VERSION ""

NS_ :

BS_:

BU_: MINI_CELKA ACHTER_BOARD FORE_BOARD ODESC RPI

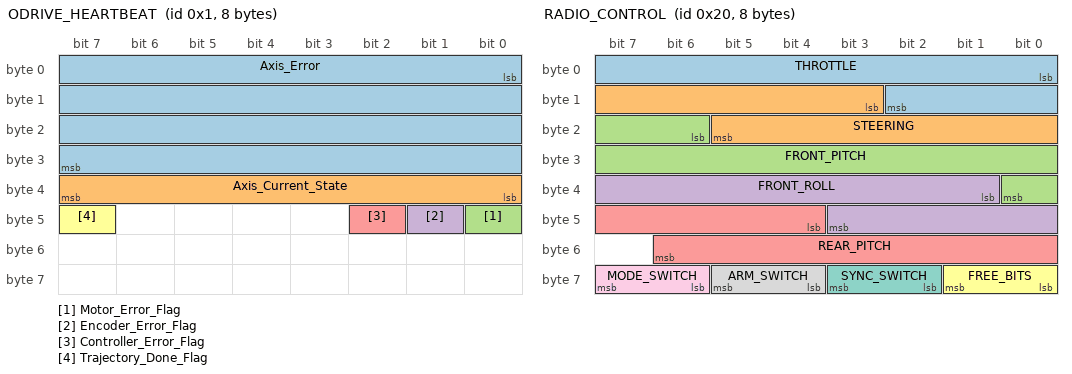
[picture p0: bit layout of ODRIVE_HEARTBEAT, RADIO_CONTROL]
BO_ 1 ODRIVE_HEARTBEAT: 8 ODESC
    SG_ Axis_Error              : 0|32@1+  (1,0) [0|4294967295] ""  Vector_XXX
    SG_ Axis_Current_State      : 32|8@1+  (1,0) [0|255]           ""  Vector_XXX
    SG_ Motor_Error_Flag        : 40|1@1+  (1,0) [0|1]             ""  Vector_XXX
    SG_ Encoder_Error_Flag      : 41|1@1+  (1,0) [0|1]             ""  Vector_XXX
    SG_ Controller_Error_Flag   : 42|1@1+  (1,0) [0|1]             ""  Vector_XXX
    SG_ Trajectory_Done_Flag    : 47|1@1+  (1,0) [0|1]             ""  Vector_XXX

BO_ 7 ODRIVE_SET_REQUESTED_STATE: 4 ODESC
	SG_ Axis_Requested_State : 0|32@1+ (1,0) [0|4294967295] "" Vector_XXX

BO_ 13 ODRIVE_SET_INPUT_VEL: 8 ODESC
    SG_ Input_Vel               : 0|32@1+  (1,0) [0|0] "FLOAT32_IEEE" Vector_XXX
    SG_ Torque_FF               : 32|32@1+ (1,0) [0|0] "FLOAT32_IEEE" Vector_XXX

BO_ 20 ODRIVE_GET_IQ: 8 ODESC
    SG_ Iq_Setpoint             : 0|32@1+  (1,0) [0|0] "FLOAT32_IEEE" Vector_XXX
    SG_ Iq_Measured             : 32|32@1+ (1,0) [0|0] "FLOAT32_IEEE" Vector_XXX

BO_ 21 ODRIVE_GET_SENSORLESS_ESTIMATES: 8 ODESC
    SG_ Sensorless_Pos_Estimate : 0|32@1+  (1,0) [0|0] "FLOAT32_IEEE" Vector_XXX
    SG_ Sensorless_Vel_Estimate : 32|32@1+ (1,0) [0|0] "FLOAT32_IEEE" Vector_XXX

BO_ 23 ODRIVE_GET_BUS_VOLTAGE_CURRENT: 8 ODESC
    SG_ Bus_Voltage 		: 0|32@1+  (1,0) [0|0] "V FLOAT32_IEEE"  Vector_XXX
    SG_ Bus_Current             : 32|32@1+ (1,0) [0|0] "A FLOAT32_IEEE" Vector_XXX

BO_ 24 ODRIVE_CLEAR_ERRORS: 0 ODESC

BO_ 32 RADIO_CONTROL	:	8	ACHTER_BOARD
	SG_ THROTTLE	:	0|11@1-		(1,0)	[-1000|1000]	"permile"	Vector__XXX
	SG_ STEERING	:	11|11@1-	(1,0)	[-1000|1000]	"permile"	Vector__XXX
	SG_ FRONT_PITCH	:	22|11@1-	(1,0)	[-1000|1000]	"permile"	Vector__XXX
	SG_ FRONT_ROLL	:	33|11@1-	(1,0)	[-1000|1000]	"permile"	Vector__XXX
	SG_ REAR_PITCH	:	44|11@1-	(1,0)	[-1000|1000]	"permile"	Vector__XXX

	SG_ FREE_BITS	:	56|2@1+	(1,0)	[0|15]	"-"	Vector__XXX

	SG_ SYNC_SWITCH	:	58|2@1+	(1,0)	[0|3]	"-"	Vector__XXX
	SG_ ARM_SWITCH	:	60|2@1+	(1,0)	[0|3]	"-"	Vector__XXX
	SG_ MODE_SWITCH	:	62|2@1+	(1,0)	[0|3]	"-"	Vector__XXX

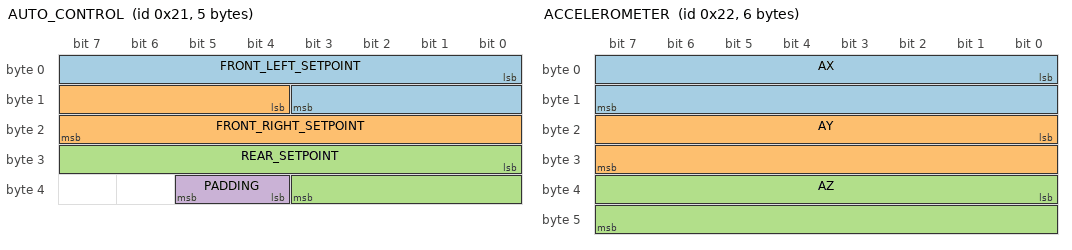
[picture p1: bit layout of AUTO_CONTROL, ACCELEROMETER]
BO_ 33 AUTO_CONTROL	:	5	RPI
	SG_ FRONT_LEFT_SETPOINT  : 0|12@1-  (0.01,0) [-6|12] "deg" Vector__XXX
	SG_ FRONT_RIGHT_SETPOINT : 12|12@1- (0.01,0) [-6|12] "deg" Vector__XXX
	SG_ REAR_SETPOINT	 : 24|12@1- (0.01,0) [-6|12] "deg" Vector__XXX

	SG_ PADDING : 36|2@1+	(1,0) [0|3] "" Vector__XXX

BO_ 34 ACCELEROMETER	:	6	FORE_BOARD
	SG_ AX : 0|16@1- (0.00006103515625, 0) [-2|2] "g" Vector__XXX
	SG_ AY : 16|16@1- (0.00006103515625, 0) [-2|2] "g" Vector__XXX
	SG_ AZ : 32|16@1- (0.00006103515625, 0) [-2|2] "g" Vector__XXX

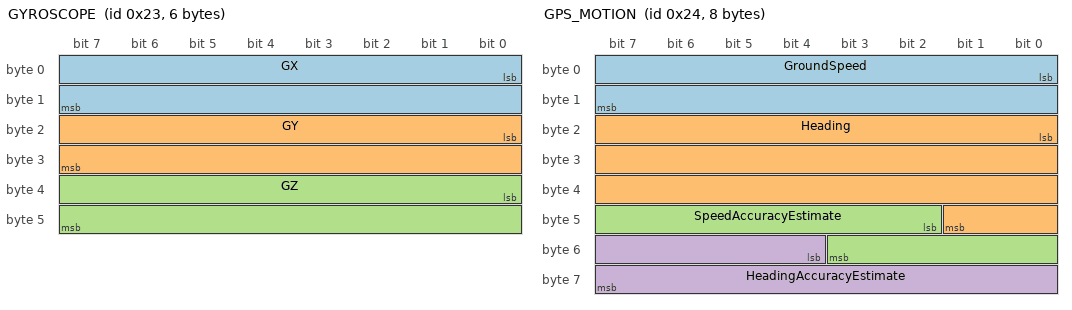
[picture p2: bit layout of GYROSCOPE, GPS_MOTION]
BO_ 35 GYROSCOPE	:	6	FORE_BOARD
	SG_ GX : 0|16@1- (0.0609756097560976, 0) [-2000|2000] "deg/s" Vector__XXX
	SG_ GY : 16|16@1- (0.0609756097560976, 0) [-2000|2000] "deg/s" Vector__XXX
	SG_ GZ : 32|16@1- (0.0609756097560976, 0) [-2000|2000] "deg/s" Vector__XXX

BO_ 36 GPS_MOTION: 8 FORE_BOARD
    SG_ GroundSpeed : 0|16@1+ (0.001,0) [0|60] "m/s" Vector__XXX
    SG_ Heading     : 16|26@1+ (1e-5,0) [0|360] "deg" Vector__XXX
    SG_ SpeedAccuracyEstimate : 42|10@1+ (0.004,0) [0|4.092] "m/s" Vector__XXX
    SG_ HeadingAccuracyEstimate : 52|12@1+ (0.01,0) [0|40.95] "deg" Vector__XXX

BO_ 37 GPS_POSITION: 8 FORE_BOARD
    SG_ Latitude  : 0|32@1- (1e-7,0) [-90|90] "deg" Vector__XXX
    SG_ Longitude : 32|32@1- (1e-7,0) [-180|180] "deg" Vector__XXX

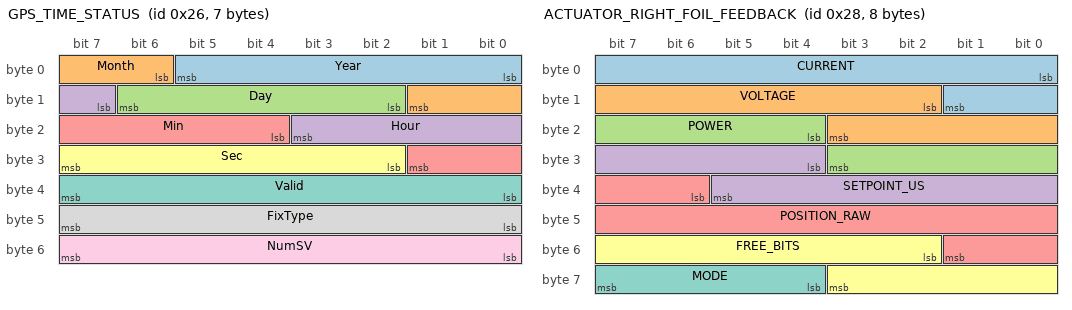
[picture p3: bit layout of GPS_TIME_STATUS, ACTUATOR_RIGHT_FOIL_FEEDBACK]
BO_ 38 GPS_TIME_STATUS: 7 FORE_BOARD
    SG_ Year  : 0|6@1+  (1,2020) [2020|2083] "year"   Vector__XXX
    SG_ Month : 6|4@1+  (1,0)    [1|12]      "month"  Vector__XXX
    SG_ Day   : 10|5@1+ (1,0)    [1|31]      "day"   Vector__XXX
    SG_ Hour  : 15|5@1+ (1,0)    [0|23]      "hour"   Vector__XXX
    SG_ Min   : 20|6@1+ (1,0)    [0|59]      "minute" Vector__XXX
    SG_ Sec   : 26|6@1+ (1,0)    [0|60]      "second"   Vector__XXX
    SG_ Valid : 32|8@1+ (1,0)    [0|15]      ""    Vector__XXX
	SG_ FixType     : 40|8@1+ (1,0) [0|5] 	 "" Vector__XXX
    SG_ NumSV       : 48|8@1+ (1,0) [0|50] 	 "" Vector__XXX

    0 "NO_FIX"
    1 "DEAD_RECKONING"
    2 "2D_FIX"
    3 "3D_FIX"
    4 "GNSS_DR_COMBINED"
    5 "TIME_ONLY";

CM_ SG_ 38 Valid "Validity flags: bit0=validDate, bit1=validTime, bit2=fullyResolved, bit3=validMag";

BO_ 39 ACTUATOR_CONFIGURATION	:	1	MINI_CELKA
	SG_ REQUEST	:	0|4@1+	(1,0)	[0|3]	"-"	Vector_XXX
	SG_ ACTUATOR	:	4|4@1+	(1,0)	[0|3]	"-"	Vector_XXX

	VAL_ 39 REQUEST 0 "NONE" 1 "ON" 2 "OFF" 3 "AUTO_CALIBRATION";
	VAL_ 39 ACTUATOR 0 "NONE" 1 "STEERING" 2 "RIGHT_FOIL" 3 "LEFT_FOIL" 4 "REAR_FOIL";

BO_ 40 ACTUATOR_RIGHT_FOIL_FEEDBACK	:	8	FORE_BOARD
	SG_ CURRENT		:	0|10@1-	(0.002,0)	[-1.0|1.0]	"A"	Vector__XXX
	SG_ VOLTAGE		:	10|10@1+	(0.003,3.6)	[3.6|6.6]	"V"	Vector__XXX
	SG_ POWER		:	20|8@1-	(0.05,0)	[-6|6]		"W"	Vector__XXX

	SG_ SETPOINT_US		:	28|10@1+	(1,988)		[988|2011]	"us"	Vector__XXX
	SG_ POSITION_RAW	:	38|12@1+	(1,0)		[0|4091]	"-"	Vector__XXX

	SG_ FREE_BITS		:	50|10@1+	(1,0)	[0|1023]	"-"	Vector__XXX

	SG_ MODE		:	60|4@1+	(1,0)	[0|15]	"-"	Vector__XXX

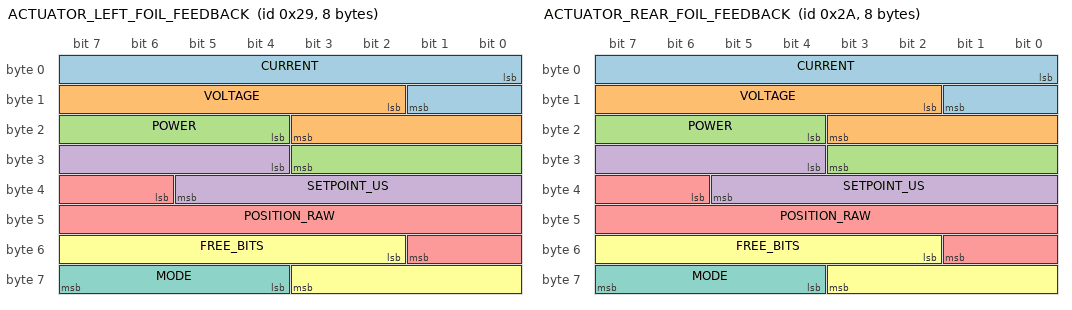
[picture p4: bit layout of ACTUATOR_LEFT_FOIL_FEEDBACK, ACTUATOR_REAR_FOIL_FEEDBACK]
BO_ 41 ACTUATOR_LEFT_FOIL_FEEDBACK	:	8	FORE_BOARD
	SG_ CURRENT		:	0|10@1-	(0.002,0)	[-1.0|1.0]	"A"	Vector__XXX
	SG_ VOLTAGE		:	10|10@1+	(0.003,3.6)	[3.6|6.6]	"V"	Vector__XXX
	SG_ POWER		:	20|8@1-	(0.05,0)	[-6|6]		"W"	Vector__XXX

	SG_ SETPOINT_US		:	28|10@1+	(1,988)		[988|2011]	"us"	Vector__XXX
	SG_ POSITION_RAW	:	38|12@1+	(1,0)		[0|4091]	"-"	Vector__XXX

	SG_ FREE_BITS		:	50|10@1+	(1,0)	[0|1023]	"-"	Vector__XXX

	SG_ MODE		:	60|4@1+	(1,0)	[0|15]	"-"	Vector__XXX

BO_ 42 ACTUATOR_REAR_FOIL_FEEDBACK	:	8	ACHTER_BOARD
	SG_ CURRENT		:	0|10@1-	(0.002,0)	[-1.0|1.0]	"A"	Vector__XXX
	SG_ VOLTAGE		:	10|10@1+	(0.003,3.6)	[3.6|6.6]	"V"	Vector__XXX
	SG_ POWER		:	20|8@1-	(0.05,0)	[-6|6]		"W"	Vector__XXX

	SG_ SETPOINT_US		:	28|10@1+	(1,988)		[988|2011]	"us"	Vector__XXX
	SG_ POSITION_RAW	:	38|12@1+	(1,0)		[0|4091]	"-"	Vector__XXX

	SG_ FREE_BITS		:	50|10@1+	(1,0)	[0|1023]	"-"	Vector__XXX

	SG_ MODE		:	60|4@1+	(1,0)	[0|15]	"-"	Vector__XXX

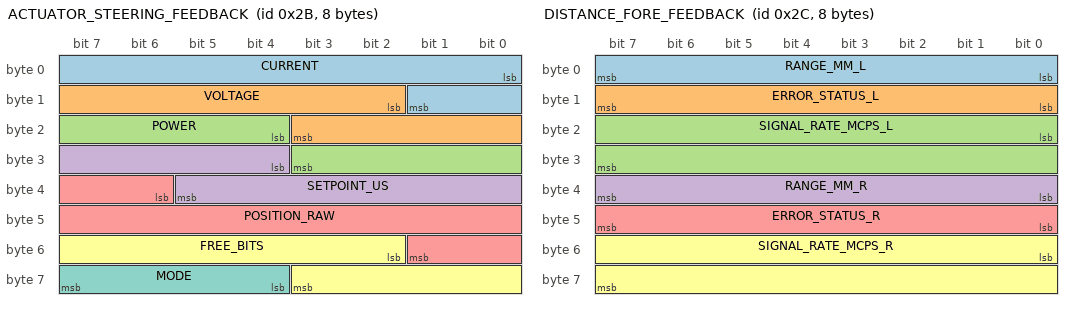
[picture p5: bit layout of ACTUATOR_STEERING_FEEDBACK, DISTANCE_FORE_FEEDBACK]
BO_ 43 ACTUATOR_STEERING_FEEDBACK	:	8	ACHTER_BOARD
	SG_ CURRENT		:	0|10@1-	(0.002,0)	[-1.0|1.0]	"A"	Vector__XXX
	SG_ VOLTAGE		:	10|10@1+	(0.003,3.6)	[3.6|6.6]	"V"	Vector__XXX
	SG_ POWER		:	20|8@1-	(0.05,0)	[-6|6]		"W"	Vector__XXX

	SG_ SETPOINT_US		:	28|10@1+	(1,988)		[988|2011]	"us"	Vector__XXX
	SG_ POSITION_RAW	:	38|12@1+	(1,0)		[0|4091]	"-"	Vector__XXX

	SG_ FREE_BITS		:	50|10@1+	(1,0)	[0|1023]	"-"	Vector__XXX

	SG_ MODE		:	60|4@1+	(1,0)	[0|15]	"-"	Vector__XXX

CM_ SG_ 43 CURRENT "Usable current range is around +/- 1A, because of 82mOhm shunt resistors used";
CM_ SG_ 43 FREE_BITS "TODO - feedback of the setpoint in degrees but the ranges are different for steering and foils";

BO_ 44 DISTANCE_FORE_FEEDBACK	:	8	FORE_BOARD
	SG_ RANGE_MM_L		: 0|8@1+ (1,0) 		[0|255] "mm" Vector__XXX
	SG_ ERROR_STATUS_L 	: 8|8@1+ (1,0)	 	[0|31] "" Vector__XXX
	SG_ SIGNAL_RATE_MCPS_L 	: 16|16@1+ (0.0078125,0) [0|10] "MCPS" Vector__XXX
	SG_ RANGE_MM_R		: 32|8@1+ (1,0) 		[0|255] "mm" Vector__XXX
	SG_ ERROR_STATUS_R 	: 40|8@1+ (1,0)	 	[0|31] "" Vector__XXX
	SG_ SIGNAL_RATE_MCPS_R	: 48|16@1+ (0.0078125,0) [0|10] "MCPS" Vector__XXX

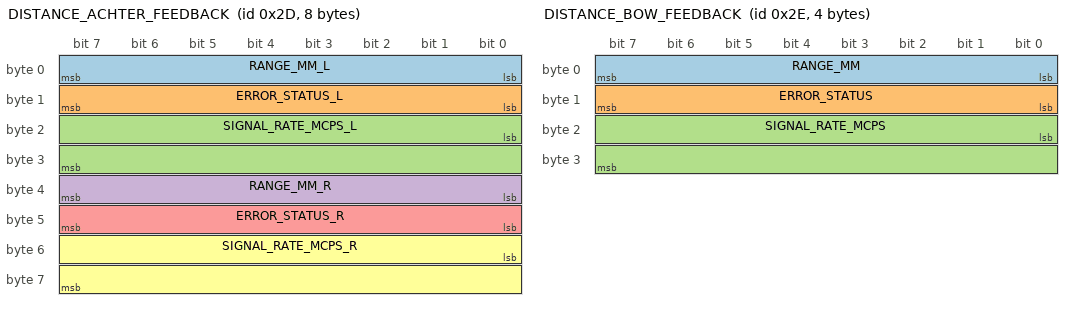
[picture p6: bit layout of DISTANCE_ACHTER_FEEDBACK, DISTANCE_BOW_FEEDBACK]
BO_ 45 DISTANCE_ACHTER_FEEDBACK	:	8	ACHTER_BOARD
	SG_ RANGE_MM_L		: 0|8@1+ (1,0) 		[0|255] "mm" Vector__XXX
	SG_ ERROR_STATUS_L 	: 8|8@1+ (1,0)	 	[0|31] "" Vector__XXX
	SG_ SIGNAL_RATE_MCPS_L 	: 16|16@1+ (0.0078125,0) [0|10] "MCPS" Vector__XXX
	SG_ RANGE_MM_R		: 32|8@1+ (1,0) 		[0|255] "mm" Vector__XXX
	SG_ ERROR_STATUS_R 	: 40|8@1+ (1,0)	 	[0|31] "" Vector__XXX
	SG_ SIGNAL_RATE_MCPS_R	: 48|16@1+ (0.0078125,0) [0|10] "MCPS" Vector__XXX

BO_ 46 DISTANCE_BOW_FEEDBACK	:	4	MINI_CELKA
	SG_ RANGE_MM		: 0|8@1+ (1,0) 		[0|255] "mm" Vector__XXX
	SG_ ERROR_STATUS	: 8|8@1+ (1,0)	 	[0|31] "" Vector__XXX
	SG_ SIGNAL_RATE_MCPS	: 16|16@1+ (0.0078125,0) [0|10] "MCPS" Vector__XXX
